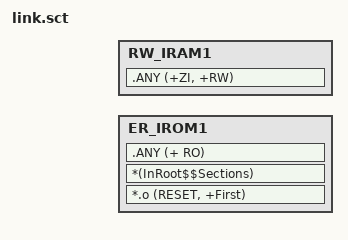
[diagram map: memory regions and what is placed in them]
#! armclang -E --target=arm-arm-none-eabi -mcpu=cortex-m33 -xc -I $SDK_ROOT/drivers/cmsis/sf32lb56x -I $BSP_ROOT -I ./linker_scripts
#include "rtconfig.h"
#include "mem_map.h"

; *************************************************************
; *** Scatter-Loading Description File generated by uVision ***
; *************************************************************

LR_IROM1 FLASH_BOOT_LOADER_START_ADDR FLASH_BOOT_LOADER_SIZE {    ; load region size_region, 
  ER_IROM1 FLASH_BOOT_LOADER_START_ADDR FLASH_BOOT_LOADER_SIZE {  ; load address = execution address
   *.o (RESET, +First)
   *(InRoot$$Sections)
   .ANY (+ RO)
  }
  
  RW_IRAM1 BOOTLOADER_RAM_DATA_START_ADDR BOOTLOADER_RAM_DATA_SIZE  {  ; RW data
   .ANY (+ZI, +RW)
  }
}
